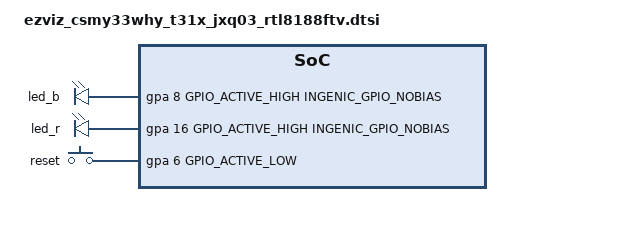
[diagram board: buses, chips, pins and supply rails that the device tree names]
// Ezviz CS-MY3-3WHY (T31X, JXQ03, RTL8188FTV) per-board GPIO definitions.
// Injected into the kernel 4.4+ device tree; ignored on 3.10.

#include <dt-bindings/gpio/gpio.h>
#include <dt-bindings/input/input.h>
#include <dt-bindings/pinctrl/ingenic-pinctrl.h>

/ {
	gpio-leds {
		compatible = "gpio-leds";

		led_b {
			label = "led_b";
			gpios = <&gpa 8 GPIO_ACTIVE_HIGH INGENIC_GPIO_NOBIAS>;
			default-state = "off";
		};

		led_r {
			label = "led_r";
			gpios = <&gpa 16 GPIO_ACTIVE_HIGH INGENIC_GPIO_NOBIAS>;
			default-state = "off";
		};
	};
};

/* Card detect; the family tree carries the reference pin. */
&msc0 {
	ingenic,cd-gpios = <&gpb 31 GPIO_ACTIVE_LOW INGENIC_GPIO_PULLUP>;
};

/ {
	gpio-keys {
		compatible = "gpio-keys";
		label = "gpio-keys";

		reset {
			label = "reset";
			linux,code = <KEY_ENTER>;
			gpios = <&gpa 6 GPIO_ACTIVE_LOW INGENIC_GPIO_PULLUP>;
		};
	};
};
